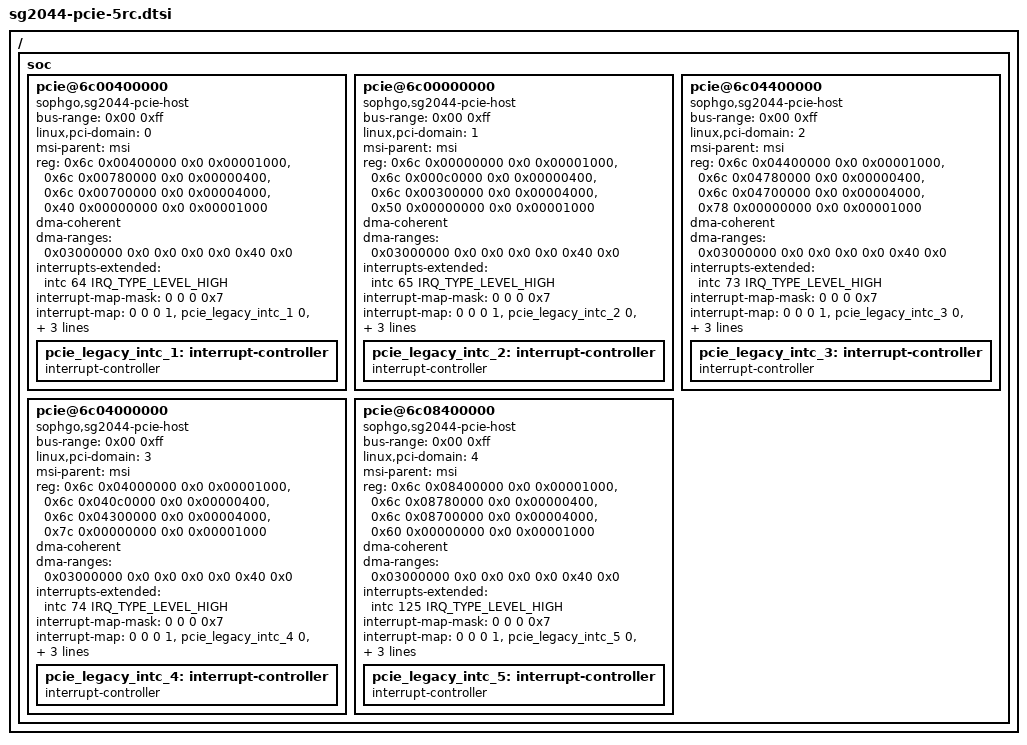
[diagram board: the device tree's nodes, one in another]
// SPDX-License-Identifier: (GPL-2.0 OR MIT)
/*
 * Copyright (C) 2022 Sophgo Technology Inc. All rights reserved.
 */

#include <dt-bindings/interrupt-controller/irq.h>

/ {
    soc {
	pcie@6c00400000 {
		compatible = "sophgo,sg2044-pcie-host";
		device_type = "pci";
		#address-cells = <3>;
		#size-cells = <2>;

		bus-range = <0x00 0xff>;
		linux,pci-domain = <0>;
		msi-parent = <&msi>;
		reg = <0x6c 0x00400000  0x0 0x00001000>,
		      <0x6c 0x00780000  0x0 0x00000400>,
		      <0x6c 0x00700000  0x0 0x00004000>,
		      <0x40 0x00000000  0x0 0x00001000>;
		reg-names = "dbi", "ctrl_base", "atu", "config";
		dma-coherent;
		// IO, check IO_SPACE_LIMIT
		// 32bit prefetchable memory
		// 32bit non-prefetchable memory
		// 64bit prefetchable memory
		// 64bit non-prefetchable memory
		ranges = <0x01000000 0x0  0x00000000  0x40 0x10000000  0x0 0x00200000>,
			 <0x42000000 0x0  0x00000000  0x0  0x00000000  0x0 0x04000000>,
			 <0x02000000 0x0  0x04000000  0x0  0x04000000  0x0 0x04000000>,
			 <0x43000000 0x44 0x00000000  0x44 0x00000000  0x4 0x00000000>,
			 <0x03000000 0x42 0x00000000  0x42 0x00000000  0x2 0x00000000>;
		dma-ranges = <0x03000000 0x0 0x0 0x0 0x0 0x40 0x0>;

		interrupts-extended = <&intc 64 IRQ_TYPE_LEVEL_HIGH>;
		interrupt-names = "pcie_irq";
		#interrupt-cells = <1>;
		interrupt-map-mask = <0 0 0 0x7>;
		interrupt-map = <0 0 0 1 &pcie_legacy_intc_1 0>,
				<0 0 0 2 &pcie_legacy_intc_1 1>,
				<0 0 0 3 &pcie_legacy_intc_1 2>,
				<0 0 0 4 &pcie_legacy_intc_1 3>;

		status = "okay";

		pcie_legacy_intc_1: interrupt-controller {
			#address-cells = <0>;
			#interrupt-cells = <1>;
			interrupt-controller;
		};
	};

	pcie@6c00000000 {
		compatible = "sophgo,sg2044-pcie-host";
		device_type = "pci";
		#address-cells = <3>;
		#size-cells = <2>;

		bus-range = <0x00 0xff>;
		linux,pci-domain = <1>;
		msi-parent = <&msi>;
		reg = <0x6c 0x00000000  0x0 0x00001000>,
		      <0x6c 0x000c0000  0x0 0x00000400>,
		      <0x6c 0x00300000  0x0 0x00004000>,
		      <0x50 0x00000000  0x0 0x00001000>;
		reg-names = "dbi", "ctrl_base", "atu", "config";
		dma-coherent;
		// IO, check IO_SPACE_LIMIT
		// 32bit prefetchable memory
		// 32bit non-prefetchable memory
		// 64bit prefetchable memory
		// 64bit non-prefetchable memory
		ranges = <0x01000000 0x0  0x00000000  0x50 0x10000000  0x0 0x00200000>,
			 <0x42000000 0x0  0x10000000  0x0  0x10000000  0x0 0x04000000>,
			 <0x02000000 0x0  0x14000000  0x0  0x14000000  0x0 0x04000000>,
			 <0x43000000 0x54 0x00000000  0x54 0x00000000  0x4 0x00000000>,
			 <0x03000000 0x52 0x00000000  0x52 0x00000000  0x2 0x00000000>;
		dma-ranges = <0x03000000 0x0 0x0 0x0 0x0 0x40 0x0>;

		interrupts-extended = <&intc 65 IRQ_TYPE_LEVEL_HIGH>;
		interrupt-names = "pcie_irq";
		#interrupt-cells = <1>;
		interrupt-map-mask = <0 0 0 0x7>;
		interrupt-map = <0 0 0 1 &pcie_legacy_intc_2 0>,
				<0 0 0 2 &pcie_legacy_intc_2 1>,
				<0 0 0 3 &pcie_legacy_intc_2 2>,
				<0 0 0 4 &pcie_legacy_intc_2 3>;

		status = "okay";

		pcie_legacy_intc_2: interrupt-controller {
			#address-cells = <0>;
			#interrupt-cells = <1>;
			interrupt-controller;
		};
	};

	pcie@6c04400000 {
		compatible = "sophgo,sg2044-pcie-host";
		device_type = "pci";
		#address-cells = <3>;
		#size-cells = <2>;

		bus-range = <0x00 0xff>;
		linux,pci-domain = <2>;
		msi-parent = <&msi>;
		reg = <0x6c 0x04400000  0x0 0x00001000>,
		      <0x6c 0x04780000  0x0 0x00000400>,
		      <0x6c 0x04700000  0x0 0x00004000>,
		      <0x78 0x00000000  0x0 0x00001000>;
		reg-names = "dbi", "ctrl_base", "atu", "config";
		dma-coherent;
		// IO, check IO_SPACE_LIMIT
		// 32bit prefetchable memory
		// 32bit non-prefetchable memory
		// 64bit prefetchable memory
		// 64bit non-prefetchable memory
		ranges = <0x01000000 0x0  0x00000000  0x78 0x10000000  0x0 0x00200000>,
			 <0x42000000 0x0  0x20000000  0x0  0x20000000  0x0 0x04000000>,
			 <0x02000000 0x0  0x24000000  0x0  0x24000000  0x0 0x04000000>,
			 <0x43000000 0x79 0x00000000  0x79 0x00000000  0x1 0x00000000>,
			 <0x03000000 0x78 0x80000000  0x78 0x80000000  0x0 0x80000000>;
		dma-ranges = <0x03000000 0x0 0x0 0x0 0x0 0x40 0x0>;

		interrupts-extended = <&intc 73 IRQ_TYPE_LEVEL_HIGH>;
		interrupt-names = "pcie_irq";
		#interrupt-cells = <1>;
		interrupt-map-mask = <0 0 0 0x7>;
		interrupt-map = <0 0 0 1 &pcie_legacy_intc_3 0>,
				<0 0 0 2 &pcie_legacy_intc_3 1>,
				<0 0 0 3 &pcie_legacy_intc_3 2>,
				<0 0 0 4 &pcie_legacy_intc_3 3>;

		status = "okay";

		pcie_legacy_intc_3: interrupt-controller {
			#address-cells = <0>;
			#interrupt-cells = <1>;
			interrupt-controller;
		};
	};

	pcie@6c04000000 {
		compatible = "sophgo,sg2044-pcie-host";
		device_type = "pci";
		#address-cells = <3>;
		#size-cells = <2>;

		bus-range = <0x00 0xff>;
		linux,pci-domain = <3>;
		msi-parent = <&msi>;
		reg = <0x6c 0x04000000  0x0 0x00001000>,
		      <0x6c 0x040c0000  0x0 0x00000400>,
		      <0x6c 0x04300000  0x0 0x00004000>,
		      <0x7c 0x00000000  0x0 0x00001000>;
		reg-names = "dbi", "ctrl_base", "atu", "config";
		dma-coherent;
		// IO, check IO_SPACE_LIMIT
		// 32bit prefetchable memory
		// 32bit non-prefetchable memory
		// 64bit prefetchable memory
		// 64bit non-prefetchable memory
		ranges = <0x01000000 0x0  0x00000000  0x7c 0x10000000  0x0 0x00200000>,
			 <0x42000000 0x0  0x30000000  0x0  0x30000000  0x0 0x04000000>,
			 <0x02000000 0x0  0x34000000  0x0  0x34000000  0x0 0x04000000>,
			 <0x43000000 0x7d 0x00000000  0x7d 0x00000000  0x1 0x00000000>,
			 <0x03000000 0x7c 0x80000000  0x7c 0x80000000  0x0 0x80000000>;
		dma-ranges = <0x03000000 0x0 0x0 0x0 0x0 0x40 0x0>;

		interrupts-extended = <&intc 74 IRQ_TYPE_LEVEL_HIGH>;
		interrupt-names = "pcie_irq";
		#interrupt-cells = <1>;
		interrupt-map-mask = <0 0 0 0x7>;
		interrupt-map = <0 0 0 1 &pcie_legacy_intc_4 0>,
				<0 0 0 2 &pcie_legacy_intc_4 1>,
				<0 0 0 3 &pcie_legacy_intc_4 2>,
				<0 0 0 4 &pcie_legacy_intc_4 3>;

		status = "okay";

		pcie_legacy_intc_4: interrupt-controller {
			#address-cells = <0>;
			#interrupt-cells = <1>;
			interrupt-controller;
		};
	};

	pcie@6c08400000 {
		compatible = "sophgo,sg2044-pcie-host";
		device_type = "pci";
		#address-cells = <3>;
		#size-cells = <2>;

		bus-range = <0x00 0xff>;
		linux,pci-domain = <4>;
		msi-parent = <&msi>;
		reg = <0x6c 0x08400000  0x0 0x00001000>,
		      <0x6c 0x08780000  0x0 0x00000400>,
		      <0x6c 0x08700000  0x0 0x00004000>,
		      <0x60 0x00000000  0x0 0x00001000>;
		reg-names = "dbi", "ctrl_base", "atu", "config";
		dma-coherent;
		// IO, check IO_SPACE_LIMIT
		// 32bit prefetchable memory
		// 32bit non-prefetchable memory
		// 64bit prefetchable memory
		// 64bit non-prefetchable memory
		ranges = <0x01000000 0x0  0x00000000  0x60 0x10000000  0x0 0x00200000>,
			 <0x42000000 0x0  0x40000000  0x0  0x40000000  0x0 0x04000000>,
			 <0x02000000 0x0  0x44000000  0x0  0x44000000  0x0 0x04000000>,
			 <0x43000000 0x62 0x00000000  0x62 0x00000000  0x2 0x00000000>,
			 <0x03000000 0x61 0x00000000  0x61 0x00000000  0x1 0x00000000>;
		dma-ranges = <0x03000000 0x0 0x0 0x0 0x0 0x40 0x0>;

		interrupts-extended = <&intc 125 IRQ_TYPE_LEVEL_HIGH>;
		interrupt-names = "pcie_irq";
		#interrupt-cells = <1>;
		interrupt-map-mask = <0 0 0 0x7>;
		interrupt-map = <0 0 0 1 &pcie_legacy_intc_5 0>,
				<0 0 0 2 &pcie_legacy_intc_5 1>,
				<0 0 0 3 &pcie_legacy_intc_5 2>,
				<0 0 0 4 &pcie_legacy_intc_5 3>;

		status = "okay";

		pcie_legacy_intc_5: interrupt-controller {
			#address-cells = <0>;
			#interrupt-cells = <1>;
			interrupt-controller;
		};
	};
    };
};
